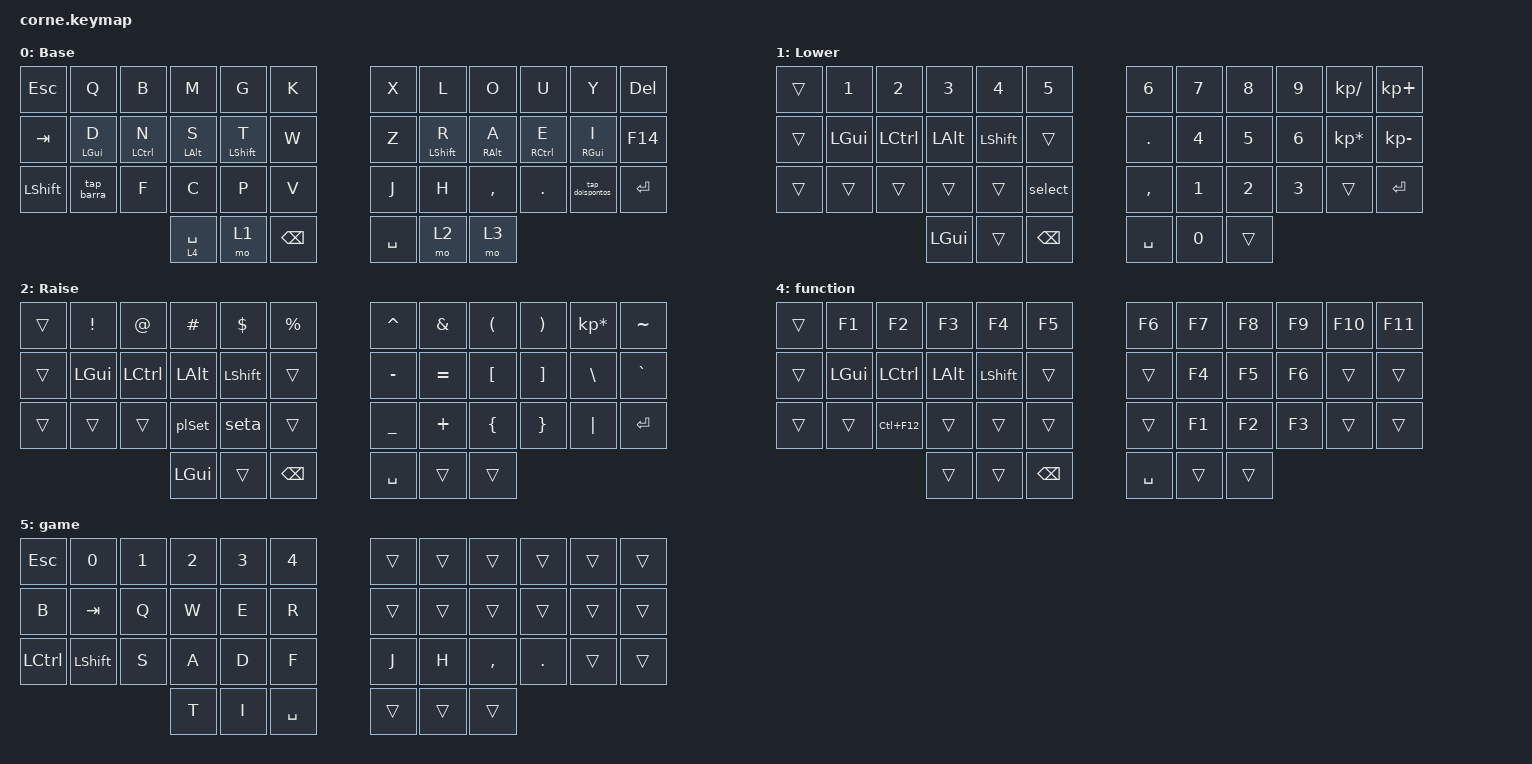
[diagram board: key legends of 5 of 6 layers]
/*
 * Copyright (c) 2020 The ZMK Contributors
 *
 * SPDX-License-Identifier: MIT
 */

#include <behaviors.dtsi>
#include <dt-bindings/zmk/bt.h>
#include <dt-bindings/zmk/keys.h>

/ {
    behaviors {
        HMR: HMR {
            compatible = "zmk,behavior-hold-tap";
            label = "HMR";
            bindings = <&kp>, <&kp>;

            #binding-cells = <2>;
            flavor = "tap-preferred";
            tapping-term-ms = <280>;
            quick-tap-ms = <175>;
            hold-trigger-key-positions = <0 1 2 3 4 5 17 16 15 14 13 12 24 25 26 27 28 29 36 37 38 39 40 41>;
            hold-trigger-on-release;
        };

        HML: HML {
            compatible = "zmk,behavior-hold-tap";
            label = "HML";
            bindings = <&kp>, <&kp>;

            #binding-cells = <2>;
            tapping-term-ms = <280>;
            quick-tap-ms = <175>;
            flavor = "tap-preferred";
            hold-trigger-key-positions = <8 6 7 9 10 11 23 22 18 19 20 21 30 31 32 33 35 34 41 40 39 38 36 37>;
            hold-trigger-on-release;
        };

        endsc: endsc {
            compatible = "zmk,behavior-hold-tap";
            label = "ENDSC";
            bindings = <&endsemi>, <&kp>;

            #binding-cells = <2>;
            tapping-term-ms = <150>;
        };

        tap_qu: tap_qu {
            compatible = "zmk,behavior-tap-dance";
            label = "TAP_QU";
            #binding-cells = <0>;
            bindings = <&qu>, <&kp Q>;

            tapping-term-ms = <250>;
        };

        tap_barra: tap_barra {
            compatible = "zmk,behavior-tap-dance";
            label = "TAP_BARRA";
            #binding-cells = <0>;
            bindings = <&kp QUESTION>, <&kp SLASH>;

            tapping-term-ms = <250>;
        };

        tap_doispontos: tap_doispontos {
            compatible = "zmk,behavior-tap-dance";
            label = "TAP_DOISPONTOS";
            #binding-cells = <0>;
            bindings = <&kp SEMICOLON>, <&kp COLON>;

            tapping-term-ms = <250>;
        };
    };

    macros {
        eh: eh {
            compatible = "zmk,behavior-macro";
            #binding-cells = <0>;
            bindings = <&kp SINGLE_QUOTE &kp E>;
            label = "EH";
        };

        atil: atil {
            compatible = "zmk,behavior-macro";
            #binding-cells = <0>;
            bindings = <&kp TILDE &kp A>;
            label = "ATIL";
        };

        ah: ah {
            compatible = "zmk,behavior-macro";
            #binding-cells = <0>;
            bindings = <&kp SINGLE_QUOTE &kp A>;
            label = "AH";
        };

        ih: ih {
            compatible = "zmk,behavior-macro";
            #binding-cells = <0>;
            bindings = <&kp SINGLE_QUOTE &kp I>;
            label = "IH";
        };

        oh: oh {
            compatible = "zmk,behavior-macro";
            #binding-cells = <0>;
            bindings = <&kp SINGLE_QUOTE &kp O>;
            label = "OH";
        };

        uh: uh {
            compatible = "zmk,behavior-macro";
            #binding-cells = <0>;
            bindings = <&kp SINGLE_QUOTE &kp U>;
            label = "UH";
        };

        otil: otil {
            compatible = "zmk,behavior-macro";
            #binding-cells = <0>;
            bindings = <&kp TILDE &kp O>;
            label = "OTIL";
        };

        endsemi: endsemi {
            compatible = "zmk,behavior-macro";
            #binding-cells = <0>;
            bindings = <&kp END &kp SEMI>;
            label = "ENDSEMI";
        };

        ao: ao {
            compatible = "zmk,behavior-macro";
            #binding-cells = <0>;
            bindings = <&kp TILDE &kp A &kp O>;
            label = "AO";
        };

        oes: oes {
            compatible = "zmk,behavior-macro";
            #binding-cells = <0>;
            bindings = <&kp TILDE &kp O &kp E &kp S>;
            label = "OES";
        };

        ca: ca {
            compatible = "zmk,behavior-macro";
            #binding-cells = <0>;
            bindings = <&kp SQT &kp C &kp A>;
            label = "CA";
        };

        cao: cao {
            compatible = "zmk,behavior-macro";
            #binding-cells = <0>;
            bindings = <&kp SQT &kp C &kp TILDE &kp A &kp O>;
            label = "CAO";
        };

        coes: coes {
            compatible = "zmk,behavior-macro";
            #binding-cells = <0>;
            bindings = <&kp SQT &kp C &kp TILDE &kp O &kp E &kp S>;
            label = "COES";
        };

        co: co {
            compatible = "zmk,behavior-macro";
            #binding-cells = <0>;
            bindings = <&kp SQT &kp C &kp O>;
            label = "CO";
        };

        cu: cu {
            compatible = "zmk,behavior-macro";
            #binding-cells = <0>;
            bindings = <&kp SQT &kp C &kp U>;
            label = "CU";
        };

        cat: cat {
            compatible = "zmk,behavior-macro";
            #binding-cells = <0>;
            bindings = <&kp SQT &kp C &kp TILDE &kp A>;
            label = "CAT";
        };

        seta: seta {
            compatible = "zmk,behavior-macro";
            #binding-cells = <0>;
            bindings = <&kp EQUAL &kp GREATER_THAN>;
            label = "SETA";
        };

        qu: qu {
            compatible = "zmk,behavior-macro";
            #binding-cells = <0>;
            bindings = <&kp Q &kp U>;
            label = "QU";
        };

        asD: asD {
            compatible = "zmk,behavior-macro";
            #binding-cells = <0>;
            bindings = <&kp SINGLE_QUOTE &kp SPACE>;
            label = "ASD";
        };

        asS: asS {
            compatible = "zmk,behavior-macro";
            #binding-cells = <0>;
            bindings = <&kp DOUBLE_QUOTES &kp SPACE>;
            label = "ASS";
        };

        ee: ee {
            compatible = "zmk,behavior-macro";
            #binding-cells = <0>;
            bindings = <&kp CARET &kp E>;
            label = "EE";
        };

        plSet: plSet {
            compatible = "zmk,behavior-macro";
            #binding-cells = <0>;
            bindings = <&kp COLON &kp EQUAL>;
            label = "PLSET";
        };

        select: select {
            compatible = "zmk,behavior-macro";
            #binding-cells = <0>;
            bindings = <&none &kp S &kp E &kp L &kp E &kp C &kp T &kp SPACE &kp STAR &kp SPACE &kp F &kp R &kp O &kp M>;
            label = "SELECT";
        };
    };

    combos {
        compatible = "zmk,combos";

        copy {
            bindings = <&kp LC(C)>;
            key-positions = <38 15>;
        };

        paste {
            bindings = <&kp LC(V)>;
            key-positions = <38 16>;
        };

        undo {
            bindings = <&kp LC(Z)>;
            key-positions = <38 13>;
        };

        cut {
            bindings = <&kp LC(X)>;
            key-positions = <14 38>;
        };

        comm {
            bindings = <&kp LC(SLASH)>;
            key-positions = <17 38>;
        };

        ih {
            bindings = <&ih>;
            key-positions = <31 22>;
        };

        eh {
            bindings = <&eh>;
            key-positions = <21 31>;
        };

        ah {
            bindings = <&ah>;
            key-positions = <31 20>;
        };

        oh {
            bindings = <&oh>;
            key-positions = <31 8>;
        };

        uh {
            bindings = <&uh>;
            key-positions = <31 9>;
        };

        ao {
            bindings = <&ao>;
            key-positions = <20 8>;
        };

        ca {
            bindings = <&ca>;
            key-positions = <27 20>;
        };

        oes {
            bindings = <&oes>;
            key-positions = <21 8>;
        };

        cu {
            bindings = <&cu>;
            key-positions = <27 9>;
        };

        co {
            bindings = <&co>;
            key-positions = <27 8>;
        };

        cao {
            bindings = <&cao>;
            key-positions = <27 20 8>;
        };

        atil {
            bindings = <&atil>;
            key-positions = <20 19>;
        };

        tab {
            bindings = <&kp TAB>;
            key-positions = <14 15>;
        };

        return {
            bindings = <&kp RET>;
            key-positions = <26 27>;
        };

        coes {
            bindings = <&coes>;
            key-positions = <27 21 8>;
        };

        copy2 {
            bindings = <&kp LC(LS(V))>;
            key-positions = <38 16 24>;
        };

        game {
            bindings = <&tog 5>;
            key-positions = <36 41>;
        };

        esc {
            bindings = <&kp ESCAPE>;
            key-positions = <1 0>;
        };

        caps {
            bindings = <&kp CAPSLOCK>;
            key-positions = <10 11>;
        };

        aspas {
            bindings = <&asS>;
            key-positions = <38 5>;
        };

        aspasDuplas {
            bindings = <&asD>;
            key-positions = <38 5 4>;
        };

        ee {
            bindings = <&ee>;
            key-positions = <22 21>;
        };

        run {
            bindings = <&kp F8>;
            key-positions = <12 13>;
        };

        saveall {
            bindings = <&kp F14>;
            key-positions = <24 25>;
        };
    };

    keymap {
        compatible = "zmk,keymap";

        default_layer {
            // -----------------------------------------------------------------------------------------
            // |  TAB |  Q  |  W  |  E  |  R  |  T  |   |  Y  |  U   |  I  |  O  |  P  | BKSP |
            // | CTRL |  A  |  S  |  D  |  F  |  G  |   |  H  |  J   |  K  |  L  |  ;  |  '   |
            // | SHFT |  Z  |  X  |  C  |  V  |  B  |   |  N  |  M   |  ,  |  .  |  /  | ESC  |
            //                    | GUI | LWR | SPC |   | ENT | RSE  | ALT |

            display-name = "Base";
            bindings = <
&kp ESC    &kp Q            &kp B         &kp M            &kp G              &kp K            &kp X      &kp L              &kp O             &kp U                 &kp Y             &kp DEL
&kp TAB    &HML LEFT_GUI D  &HML LCTRL N  &HML LEFT_ALT S  &HML LEFT_SHIFT T  &kp W            &kp Z      &HMR LEFT_SHIFT R  &HMR RIGHT_ALT A  &HMR RIGHT_CONTROL E  &HMR RIGHT_GUI I  &kp F14
&kp LSHFT  &tap_barra       &kp F         &kp C            &kp P              &kp V            &kp J      &kp H              &kp COMMA         &kp DOT               &tap_doispontos   &kp RETURN
                                          &lt 4 SPACE      &mo 1              &kp BACKSPACE    &kp SPACE  &mo 2              &mo 3
            >;
        };

        number {
            // -----------------------------------------------------------------------------------------
            // |  TAB |  1  |  2  |  3  |  4  |  5  |   |  6  |  7  |  8  |  9  |  0  | BKSP |
            // | BTCLR| BT1 | BT2 | BT3 | BT4 | BT5 |   | LFT | DWN |  UP | RGT |     |      |
            // | SHFT |     |     |     |     |     |   |     |     |     |     |     |      |
            //                    | GUI |     | SPC |   | ENT |     | ALT |

            display-name = "Lower";
            bindings = <
&trans  &kp NUMBER_1  &kp NUMBER_2  &kp NUMBER_3  &kp NUMBER_4    &kp N5           &kp NUMBER_6  &kp N7        &kp N8        &kp N9        &kp KP_DIVIDE    &kp KP_PLUS
&trans  &kp LEFT_GUI  &kp LCTRL     &kp LEFT_ALT  &kp LEFT_SHIFT  &trans           &kp PERIOD    &kp NUMBER_4  &kp N5        &kp NUMBER_6  &kp KP_MULTIPLY  &kp KP_SUBTRACT
&trans  &trans        &trans        &trans        &trans          &select          &kp COMMA     &kp NUMBER_1  &kp NUMBER_2  &kp NUMBER_3  &trans           &kp RETURN
                                    &kp LGUI      &trans          &kp BACKSPACE    &kp SPACE     &kp N0        &trans
            >;
        };

        symbols {
            // -----------------------------------------------------------------------------------------
            // |  TAB |  !  |  @  |  #  |  $  |  %  |   |  ^  |  &  |  *  |  (  |  )  | BKSP |
            // | CTRL |     |     |     |     |     |   |  -  |  =  |  [  |  ]  |  \  |  `   |
            // | SHFT |     |     |     |     |     |   |  _  |  +  |  {  |  }  | "|" |  ~   |
            //                    | GUI |     | SPC |   | ENT |     | ALT |

            display-name = "Raise";
            bindings = <
&trans  &kp EXCL      &kp AT     &kp HASH      &kp DLLR        &kp PRCNT        &kp CARET  &kp AMPS   &kp LEFT_PARENTHESIS  &kp RIGHT_PARENTHESIS  &kp KP_ASTERISK  &kp TILDE
&trans  &kp LEFT_GUI  &kp LCTRL  &kp LEFT_ALT  &kp LEFT_SHIFT  &trans           &kp MINUS  &kp EQUAL  &kp LEFT_BRACKET      &kp RBKT               &kp BSLH         &kp GRAVE
&trans  &trans        &trans     &plSet        &seta           &trans           &kp UNDER  &kp PLUS   &kp LEFT_BRACE        &kp RIGHT_BRACE        &kp PIPE         &kp RETURN
                                 &kp LGUI      &trans          &kp BACKSPACE    &kp SPACE  &trans     &trans
            >;
        };

        setas {
            bindings = <
&trans    &trans   &bt BT_CLR_ALL  &bt BT_SEL 1  &trans         &trans       &trans  &trans  &trans  &trans          &trans          &trans
&trans    &trans   &trans          &trans        &trans         &trans       &trans  &trans  &trans  &kp BACKSPACE   &kp UP_ARROW    &kp DELETE
&kp HOME  &kp END  &trans          &trans        &trans         &trans       &trans  &trans  &trans  &kp LEFT_ARROW  &kp DOWN_ARROW  &kp RIGHT
                                   &trans        &kp BACKSPACE  &kp SPACE    &trans  &trans
            >;
        };

        function {
            bindings = <
&trans  &kp F1        &kp F2       &kp F3        &kp F4          &kp F5           &kp F6     &kp F7  &kp F8  &kp F9  &kp F10  &kp F11
&trans  &kp LEFT_GUI  &kp LCTRL    &kp LEFT_ALT  &kp LEFT_SHIFT  &trans           &trans     &kp F4  &kp F5  &kp F6  &trans   &trans
&trans  &trans        &kp LC(F12)  &trans        &trans          &trans           &trans     &kp F1  &kp F2  &kp F3  &trans   &trans
                                   &trans        &trans          &kp BACKSPACE    &kp SPACE  &trans  &trans
            >;
        };

        game {
            bindings = <
&kp ESC           &kp NUMBER_0    &kp NUMBER_1  &kp NUMBER_2  &kp NUMBER_3  &kp NUMBER_4    &trans  &trans  &trans     &trans      &trans  &trans
&kp B             &kp TAB         &kp Q         &kp W         &kp E         &kp R           &trans  &trans  &trans     &trans      &trans  &trans
&kp LEFT_CONTROL  &kp LEFT_SHIFT  &kp S         &kp A         &kp D         &kp F           &kp J   &kp H   &kp COMMA  &kp PERIOD  &trans  &trans
                                                &kp T         &kp I         &kp SPACE       &trans  &trans  &trans
            >;
        };
    };
};
